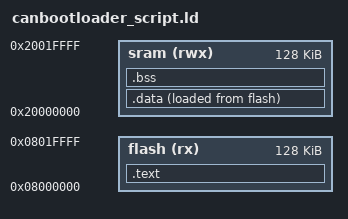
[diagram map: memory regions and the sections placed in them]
/**
 * DCS2.Pilot STM32H743 CAN bootloader linker script
 *
 * Bootloader occupies first 128KB of flash
 */

MEMORY
{
    flash  (rx) : ORIGIN = 0x08000000, LENGTH = 128K
    sram  (rwx) : ORIGIN = 0x20000000, LENGTH = 128K
}

OUTPUT_ARCH(arm)
EXTERN(_vectors)
ENTRY(__start)

SECTIONS
{
    .text :
    {
        _stext = ABSOLUTE(.);
        *(.vectors)
        . = ALIGN(32);
        *(.text .text.*)
        *(.fixup)
        *(.gnu.warning)
        *(.rodata .rodata.*)
        *(.gnu.linkonce.t.*)
        *(.glue_7)
        *(.glue_7t)
        *(.got)
        *(.gcc_except_table)
        *(.gnu.linkonce.r.*)
        _etext = ABSOLUTE(.);
    } > flash

    _eronly = ABSOLUTE(.);

    .data :
    {
        _sdata = ABSOLUTE(.);
        *(.data .data.*)
        *(.gnu.linkonce.d.*)
        CONSTRUCTORS
        _edata = ABSOLUTE(.);
    } > sram AT > flash

    .bss :
    {
        _sbss = ABSOLUTE(.);
        *(.bss .bss.*)
        *(.gnu.linkonce.b.*)
        *(COMMON)
        . = ALIGN(4);
        _ebss = ABSOLUTE(.);
    } > sram

    /* Stabs debugging sections */
    .stab 0 : { *(.stab) }
    .stabstr 0 : { *(.stabstr) }
}
